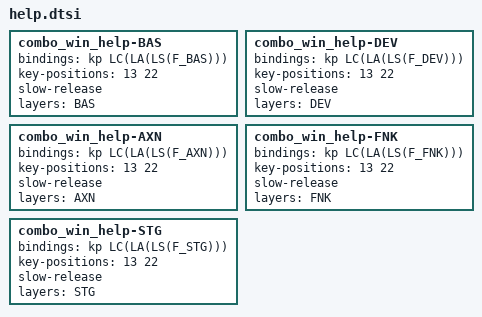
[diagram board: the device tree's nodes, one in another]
combo_win_help-BAS {
    bindings = <&kp LC(LA(LS(F_BAS)))>;
    key-positions = <13 22>;
    slow-release;
    layers = <BAS>;
};

combo_win_help-DEV {
    bindings = <&kp LC(LA(LS(F_DEV)))>;
    key-positions = <13 22>;
    slow-release;
    layers = <DEV>;
};

combo_win_help-AXN {
    bindings = <&kp LC(LA(LS(F_AXN)))>;
    key-positions = <13 22>;
    slow-release;
    layers = <AXN>;
};

combo_win_help-FNK {
    bindings = <&kp LC(LA(LS(F_FNK)))>;
    key-positions = <13 22>;
    slow-release;
    layers = <FNK>;
};

combo_win_help-STG {
    bindings = <&kp LC(LA(LS(F_STG)))>;
    key-positions = <13 22>;
    slow-release;
    layers = <STG>;
};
